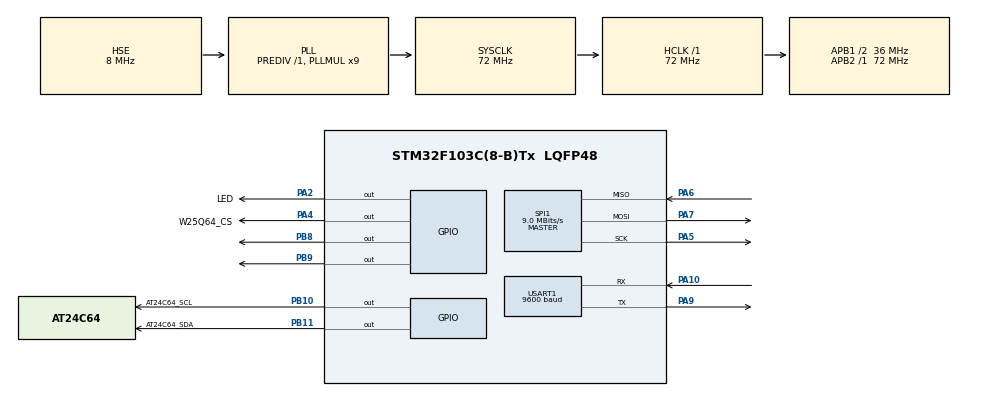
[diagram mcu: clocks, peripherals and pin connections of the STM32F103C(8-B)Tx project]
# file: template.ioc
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Dma.Request0=USART1_RX
Dma.Request1=USART1_TX
Dma.USART1_RX.0.Direction=DMA_PERIPH_TO_MEMORY
Dma.USART1_RX.0.Instance=DMA1_Channel5
Dma.USART1_RX.0.MemDataAlignment=DMA_MDATAALIGN_BYTE
Dma.USART1_RX.0.MemInc=DMA_MINC_ENABLE
Dma.USART1_RX.0.Mode=DMA_NORMAL
Dma.USART1_RX.0.PeriphDataAlignment=DMA_PDATAALIGN_BYTE
Dma.USART1_RX.0.PeriphInc=DMA_PINC_DISABLE
Dma.USART1_RX.0.Priority=DMA_PRIORITY_LOW
Dma.USART1_TX.1.Direction=DMA_MEMORY_TO_PERIPH
Dma.USART1_TX.1.Instance=DMA1_Channel4
Dma.USART1_TX.1.MemDataAlignment=DMA_MDATAALIGN_BYTE
Dma.USART1_TX.1.MemInc=DMA_MINC_ENABLE
Dma.USART1_TX.1.Mode=DMA_NORMAL
Dma.USART1_TX.1.PeriphDataAlignment=DMA_PDATAALIGN_BYTE
Dma.USART1_TX.1.PeriphInc=DMA_PINC_DISABLE
Dma.USART1_TX.1.Priority=DMA_PRIORITY_LOW
Mcu.Family=STM32F1
Mcu.Name=STM32F103C(8-B)Tx
Mcu.Package=LQFP48
NVIC.DMA1_Channel4_IRQn=true\:2\:0\:true\:false\:true\:false\:true\:true
NVIC.DMA1_Channel5_IRQn=true\:2\:0\:true\:false\:true\:false\:true\:true
NVIC.PriorityGroup=NVIC_PRIORITYGROUP_4
NVIC.TIM4_IRQn=true\:3\:0\:true\:false\:true\:true\:true\:true
NVIC.USART1_IRQn=true\:2\:0\:true\:false\:true\:true\:true\:true
PA10.Mode=Asynchronous
PA10.Signal=USART1_RX
PA2.GPIO_Label=LED
PA2.GPIO_ModeDefaultOutputPP=GPIO_MODE_OUTPUT_PP
PA2.GPIO_Speed=GPIO_SPEED_FREQ_LOW
PA2.PinState=GPIO_PIN_RESET
PA2.Signal=GPIO_Output
PA13.Mode=Serial_Wire
PA13.Signal=SYS_JTMS-SWDIO
PA14.Mode=Serial_Wire
PA14.Signal=SYS_JTCK-SWCLK
PA4.GPIO_Label=W25Q64_CS
PA4.GPIO_ModeDefaultOutputPP=GPIO_MODE_OUTPUT_PP
PA4.GPIO_PuPd=GPIO_PULLUP
PA4.GPIO_Speed=GPIO_SPEED_FREQ_HIGH
PA4.PinState=GPIO_PIN_SET
PA4.Signal=GPIO_Output
PA5.Mode=Full_Duplex_Master
PA5.Signal=SPI1_SCK
PA6.Mode=Full_Duplex_Master
PA6.Signal=SPI1_MISO
PA7.Mode=Full_Duplex_Master
PA7.Signal=SPI1_MOSI
PA9.Mode=Asynchronous
PA9.Signal=USART1_TX
PB10.GPIO_Label=AT24C64_SCL
PB10.GPIO_ModeDefaultOutputPP=GPIO_MODE_OUTPUT_OD
PB10.GPIO_PuPd=GPIO_PULLUP
PB10.GPIO_Speed=GPIO_SPEED_FREQ_MEDIUM
PB10.Signal=GPIO_Output
PB11.GPIO_Label=AT24C64_SDA
PB11.GPIO_ModeDefaultOutputPP=GPIO_MODE_OUTPUT_OD
PB11.GPIO_PuPd=GPIO_PULLUP
PB11.GPIO_Speed=GPIO_SPEED_FREQ_MEDIUM
PB11.Signal=GPIO_Output
PB8.GPIO_ModeDefaultOutputPP=GPIO_MODE_OUTPUT_OD
PB8.GPIO_PuPd=GPIO_PULLUP
PB8.GPIO_Speed=GPIO_SPEED_FREQ_MEDIUM
PB8.Signal=GPIO_Output
PB9.GPIO_ModeDefaultOutputPP=GPIO_MODE_OUTPUT_OD
PB9.GPIO_PuPd=GPIO_PULLUP
PB9.GPIO_Speed=GPIO_SPEED_FREQ_MEDIUM
PB9.Signal=GPIO_Output
PC14-OSC32_IN.Mode=LSE-External-Oscillator
PC14-OSC32_IN.Signal=RCC_OSC32_IN
PC15-OSC32_OUT.Mode=LSE-External-Oscillator
PC15-OSC32_OUT.Signal=RCC_OSC32_OUT
PD0-OSC_IN.Mode=HSE-External-Oscillator
PD0-OSC_IN.Signal=RCC_OSC_IN
PD1-OSC_OUT.Mode=HSE-External-Oscillator
PD1-OSC_OUT.Signal=RCC_OSC_OUT
ProjectManager.HeapSize=0x200
ProjectManager.StackSize=0x400
ProjectManager.TargetToolchain=MDK-ARM V5.32
RCC.AHBFreq_Value=72000000
RCC.APB1CLKDivider=RCC_HCLK_DIV2
RCC.APB1Freq_Value=36000000
RCC.APB1TimFreq_Value=72000000
RCC.APB2Freq_Value=72000000
RCC.APB2TimFreq_Value=72000000
RCC.HCLKFreq_Value=72000000
RCC.PLLMUL=RCC_PLL_MUL9
RCC.PLLSourceVirtual=RCC_PLLSOURCE_HSE
RCC.SYSCLKFreq_VALUE=72000000
RCC.SYSCLKSource=RCC_SYSCLKSOURCE_PLLCLK
RCC.USBFreq_Value=72000000
SPI1.BaudRatePrescaler=SPI_BAUDRATEPRESCALER_8
SPI1.BaudRate_Prescaler=SPI_BAUDRATEPRESCALER_8
SPI1.CLKPhase=SPI_PHASE_1EDGE
SPI1.CLKPolarity=SPI_POLARITY_LOW
SPI1.CRCCalculation=SPI_CRCCALCULATION_DISABLE
SPI1.CalculateBaudRate=9.0 MBits/s
SPI1.DataSize=SPI_DATASIZE_8BIT
SPI1.Direction=SPI_DIRECTION_2LINES
SPI1.FirstBit=SPI_FIRSTBIT_MSB
SPI1.Mode=SPI_MODE_MASTER
SPI1.NSS=SPI_NSS_SOFT
SPI1.TIMode=SPI_TIMODE_DISABLE
SPI1.VirtualType=VM_MASTER
TIM4.Period=1000-1
TIM4.Prescaler=72-1
USART1.BaudRate=9600
USART1.VirtualMode=VM_ASYNC
VP_TIM4_VS_ClockSourceINT.Mode=Internal
board=custom

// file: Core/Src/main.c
/* USER CODE BEGIN Header */
/**
  ******************************************************************************
  * @file           : main.c
  * @brief          : Main program body
  ******************************************************************************
  * @attention
  *
  * Copyright (c) 2026 STMicroelectronics.
  * All rights reserved.
  *
  * This software is licensed under terms that can be found in the LICENSE file
  * in the root directory of this software component.
  * If no LICENSE file comes with this software, it is provided AS-IS.
  *
  ******************************************************************************
  */
/* USER CODE END Header */
#include "main.h"
#include "dma.h"
#include "spi.h"
#include "tim.h"
#include "usart.h"
#include "gpio.h"

/* USER CODE BEGIN Includes */
#include "App_reset.h"
#include "key.h"
#include "stdio.h"
#include "string.h"
/* USER CODE END Includes */

void SystemClock_Config(void);

int main(void)
{

  /* USER CODE BEGIN 1 */
  __enable_irq();   // bootloader(07) 跳转前 __disable_irq() 关了全局中断，这里必须重新打开，否则 SysTick/UART/TIM4 全失效，LED 不闪
  /* USER CODE END 1 */

  /* MCU Configuration--------------------------------------------------------*/

  /* Reset of all peripherals, Initializes the Flash interface and the Systick. */
  HAL_Init();

  /* Configure the system clock */
  SystemClock_Config();

  /* Initialize all configured peripherals */
  MX_GPIO_Init();
  MX_DMA_Init();
  MX_TIM4_Init();
  MX_USART1_UART_Init();
  MX_SPI1_Init();
  /* USER CODE BEGIN 2 */
  printf("\r\n=== boot ===\r\n");   //开机提示：每次复位（上电/点击复位）串口都会显示

  HAL_TIM_Base_Start_IT(&htim4);
  bootloader_init();          //底层：启动串口 DMA 双缓冲接收（必须先调用，否则收不到任何数据）
  App_bootloader_init();      //上层：升级状态机复位（等待 start:len 命令）

  uint32_t last_blink_tick = HAL_GetTick();   //LED 连续闪烁计时基准，观察程序运行用

  /* USER CODE END 2 */

  /* Infinite loop */
  while (1)
  {

    /* USER CODE BEGIN 3 */

    //升级状态机轮询：解析 start:len → 收帧写 flash → 校验 → 跳转 app（必须在主循环里持续调用）
    App_bootloader_work();

    //LED 连续闪烁，观察程序运行用；不影响其他功能
    if (HAL_GetTick() - last_blink_tick >= 2000)
    {
      last_blink_tick = HAL_GetTick();
      HAL_GPIO_TogglePin(LED_GPIO_Port, LED_Pin);
    }

    /* USER CODE END 3 */
   }
}

void SystemClock_Config(void)
{
  RCC_OscInitTypeDef RCC_OscInitStruct = {0};
  RCC_ClkInitTypeDef RCC_ClkInitStruct = {0};

  /** Initializes the RCC Oscillators according to the specified parameters
  * in the RCC_OscInitTypeDef structure.
  */
  RCC_OscInitStruct.OscillatorType = RCC_OSCILLATORTYPE_HSE;
  RCC_OscInitStruct.HSEState = RCC_HSE_ON;
  RCC_OscInitStruct.HSEPredivValue = RCC_HSE_PREDIV_DIV1;
  RCC_OscInitStruct.HSIState = RCC_HSI_ON;
  RCC_OscInitStruct.PLL.PLLState = RCC_PLL_ON;
  RCC_OscInitStruct.PLL.PLLSource = RCC_PLLSOURCE_HSE;
  RCC_OscInitStruct.PLL.PLLMUL = RCC_PLL_MUL9;
  if (HAL_RCC_OscConfig(&RCC_OscInitStruct) != HAL_OK)
  {
    Error_Handler();
  }

  /** Initializes the CPU, AHB and APB buses clocks
  */
  RCC_ClkInitStruct.ClockType = RCC_CLOCKTYPE_HCLK|RCC_CLOCKTYPE_SYSCLK
                              |RCC_CLOCKTYPE_PCLK1|RCC_CLOCKTYPE_PCLK2;
  RCC_ClkInitStruct.SYSCLKSource = RCC_SYSCLKSOURCE_PLLCLK;
  RCC_ClkInitStruct.AHBCLKDivider = RCC_SYSCLK_DIV1;
  RCC_ClkInitStruct.APB1CLKDivider = RCC_HCLK_DIV2;
  RCC_ClkInitStruct.APB2CLKDivider = RCC_HCLK_DIV1;

  if (HAL_RCC_ClockConfig(&RCC_ClkInitStruct, FLASH_LATENCY_2) != HAL_OK)
  {
    Error_Handler();
  }
}

void Error_Handler(void)
{
  __disable_irq();
  while (1)
  {
  }
}
